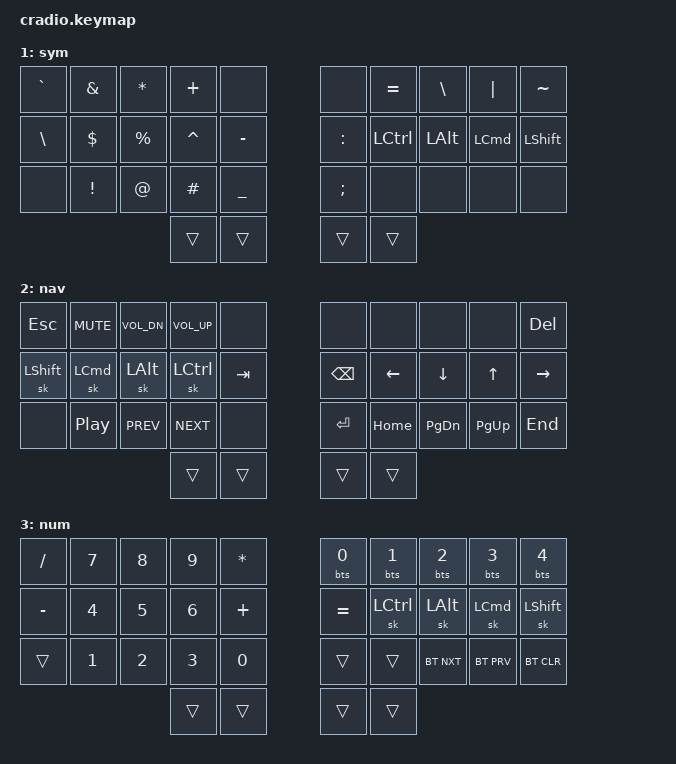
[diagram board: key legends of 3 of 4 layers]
// Copyright (c) 2022 The ZMK Contributors
// SPDX-License-Identifier: MIT

#include <behaviors.dtsi>
#include <dt-bindings/zmk/keys.h>
#include <dt-bindings/zmk/bt.h>
#include <dt-bindings/zmk/outputs.h>

// Cannot use it with keymap-drawer
/* #include "zmk-helpers/key-labels/34.h" */
#include "keypos.h"

#define BASE 0
#define SYM 1
#define NAV 2
#define NUM 3
#define VOL_DN C_VOL_DN
#define VOL_UP C_VOL_UP

#define HRML(k1,k2,k3) &hml LCMD k1  &hml LALT k2 &hml LCTRL k3
#define HRMR(k1,k2,k3) &hmr LCTRL k1 &hmr LALT k2 &hmr LCMD k3


&sk {
  release-after-ms = <2000>;
};

/ {
    macros {
        bts: bts {
            compatible = "zmk,behavior-macro-one-param";
            #binding-cells = <1>;
            bindings
                = <&out OUT_BLE>
                , <&macro_param_1to2>
                , <&bt BT_SEL MACRO_PLACEHOLDER>
                ;
        };
    };
};


/ {
    behaviors {
        hml: hml {
            compatible = "zmk,behavior-hold-tap";
            flavor = "balanced";
            tapping-term-ms = <220>;
            quick-tap-ms = <175>;                // repeat on tap-into-hold
            require-prior-idle-ms = <150>;
            #binding-cells = <2>;
            bindings = <&kp>, <&kp>;
            hold-trigger-key-positions = <KEYS_R THUMBS>;
            hold-trigger-on-release;             // delay positional check until key-release
        };

        hmr: hmr {
            compatible = "zmk,behavior-hold-tap";
            flavor = "balanced";
            tapping-term-ms = <220>;
            quick-tap-ms = <175>;                // repeat on tap-into-hold
            require-prior-idle-ms = <150>;
            #binding-cells = <2>;
            bindings = <&kp>, <&kp>;
            hold-trigger-key-positions = <KEYS_L THUMBS>;
            hold-trigger-on-release;             // delay positional check until key-release
        };

        lpar_lt: lpar_lt {
            compatible = "zmk,behavior-mod-morph";
            mods = <(MOD_LSFT | MOD_RSFT)>;
            #binding-cells = <0>;
            bindings = <&kp LPAR>, <&kp LT>;
        };

        rpar_gt: rpar_gt {
            compatible = "zmk,behavior-mod-morph";
            mods = <(MOD_LSFT | MOD_RSFT)>;
            #binding-cells = <0>;
            bindings = <&kp RPAR>, <&kp GT>;
        };

        lbrc_lbkt: lbrc_lbkt {
            compatible = "zmk,behavior-mod-morph";
            mods = <(MOD_LSFT | MOD_RSFT)>;
            #binding-cells = <0>;
            bindings = <&kp LBRC>, <&kp LBKT>;
        };

        rbrc_rbkt: rbrc_rbkt {
            compatible = "zmk,behavior-mod-morph";
            mods = <(MOD_LSFT | MOD_RSFT)>;
            #binding-cells = <0>;
            bindings = <&kp RBRC>, <&kp RBKT>;
        };
    };

    conditional_layers {
        compatible = "zmk,conditional-layers";
        tri_layer {
            if-layers = <SYM NAV>;
            then-layer = <NUM>;
        };
    };

    combos {
        compatible = "zmk,combos";

        combo_escape {
            timeout-ms = <25>;
            key-positions = <LT2 LT1>;
            bindings = <&kp ESCAPE>;
            layers = <BASE>;
        };
        combo_tab {
            timeout-ms = <25>;
            key-positions = <LM2 LM1>;
            bindings = <&kp TAB>;
            layers = <BASE>;
        };


        combo_backspace {
            timeout-ms = <25>;
            key-positions = <RT2 RT3>;
            bindings = <&kp BACKSPACE>;
            layers = <BASE>;
        };
        combo_enter {
            timeout-ms = <25>;
            key-positions = <RM1 RM2>;
            bindings = <&kp ENTER>;
            layers = <BASE>;
        };

        combo_lpar {
            timeout-ms = <50>;
            key-positions = <LT1 LM1>;
            bindings = <&lpar_lt>;
            layers = <BASE>;
        };
        combo_rpar {
            timeout-ms = <50>;
            key-positions = <RT1 RM1>;
            bindings = <&rpar_gt>;
            layers = <BASE>;
        };

        combo_lbrc {
            timeout-ms = <50>;
            key-positions = <LT2 LM2>;
            bindings = <&lbrc_lbkt>;
            layers = <BASE>;
        };
        combo_rbrc {
            timeout-ms = <50>;
            key-positions = <RT2 RM2>;
            bindings = <&rbrc_rbkt>;
            layers = <BASE>;
        };

        combo_boot {
            timeout-ms = <40>;
            key-positions = <LB4 LB3>;
            bindings = <&bootloader>;
            layers = <BASE>;
        };
    };

    keymap {
        compatible = "zmk,keymap";
        base {
            bindings = <
        //╭──────────┬──────────┬──────────┬──────────┬──────────╮   ╭──────────┬──────────┬──────────┬──────────┬──────────╮
        //│  Q       │  W       │  F       │  P       │  B       │   │  J       │  L       │  U       │  Y       │  '       │
            &kp Q      &kp W      &kp F      &kp P      &kp B          &kp J      &kp L      &kp U      &kp Y      &kp SQT
        //├──────────┼──────────┼──────────┼──────────┼──────────┤   ├──────────┼──────────┼──────────┼──────────┼──────────┤
        //│  A       │  R       │  S       │  T       │  G       │   │  M       │  N       │  E       │  I       │  O       │
            &kp A      HRML(R,     S,         T)        &kp G          &kp M      HRMR(N,     E,         I)      &kp O
        //├──────────┼──────────┼──────────┼──────────┼──────────┤   ├──────────┼──────────┼──────────┼──────────┼──────────┤
        //│  Z       │  X       │  C       │  D       │  V       │   │  K       │  H       │ , <      │ . >      │ / ?      │
            &kp Z      &kp X      &kp C      &kp D      &kp V          &kp K      &kp H      &kp COMMA  &kp DOT    &kp FSLH
        //╰──────────┴──────────┴──────────┼──────────┼──────────┤   ├──────────┼──────────┼──────────┴──────────┴──────────╯
                                            &mo NAV     &kp LSHFT      &kp SPC    &mo SYM
        //                                 ╰──────────┴──────────╯   ╰──────────┴──────────╯
            >;
        };

        sym {
            bindings = <
        //╭──────────┬──────────┬──────────┬──────────┬──────────╮   ╭──────────┬──────────┬──────────┬──────────┬──────────╮
        //│  `       │  &       │  *       │  +       │          │   │          │  =       │  \       │  |       │  ~       │
            &kp GRAVE  &kp AMPS   &kp STAR   &kp PLUS   &none          &none      &kp EQUAL  &kp BSLH   &kp PIPE   &kp TILDE
        //├──────────┼──────────┼──────────┼──────────┼──────────┤   ├──────────┼──────────┼──────────┼──────────┼──────────┤
        //│  \       │  $       │  %       │  ^       │  -       │   │  :       │          │          │          │          │
            &kp BSLH   &kp DLLR   &kp PRCNT  &kp CARET  &kp MINUS      &kp COLON  &kp LCTRL  &kp LALT   &kp LCMD   &kp LSHFT
        //├──────────┼──────────┼──────────┼──────────┼──────────┤   ├──────────┼──────────┼──────────┼──────────┼──────────┤
        //│          │  !       │  @       │  #       │  _       │   │  ;       │          │          │          │          │
            &none      &kp EXCL   &kp AT     &kp HASH   &kp UNDER      &kp SEMI   &none      &none      &none      &none
        //╰──────────┴──────────┴──────────┼──────────┼──────────┤   ├──────────┼──────────┼──────────┴──────────┴──────────╯
                                             &trans     &trans         &trans     &trans
        //                                 ╰──────────┴──────────╯   ╰──────────┴──────────╯
            >;
        };

        nav {
            bindings = <
        //╭──────────┬──────────┬──────────┬──────────┬──────────╮   ╭──────────┬──────────┬──────────┬──────────┬──────────╮
        //│  ESCAPE  │  MUTE    │ VOL DOWN │  VOL UP  │          │   │          │          │          │          │  DELETE  │
            &kp ESC   &kp C_MUTE &kp VOL_DN &kp VOL_UP  &none          &none     &none       &none       &none     &kp DEL
        //├──────────┼──────────┼──────────┼──────────┼──────────┤   ├──────────┼──────────┼──────────┼──────────┼──────────┤
        //│  SHIFT   │  CMD     │  ALT     │  CTRL    │  TAB     │   │ BSPC     │  LEFT    │  DOWN    │  UP      │ RIGHT    │
            &sk LSHFT  &sk LCMD   &sk LALT   &sk LCTRL  &kp TAB        &kp BSPC  &kp LEFT   &kp DOWN   &kp UP     &kp RIGHT
        //├──────────┼──────────┼──────────┼──────────┼──────────┤   ├──────────┼──────────┼──────────┼──────────┼──────────┤
        //│          │  PLAY    │ PREVIOUS │  NEXT    │          │   │  ENTER   │  HOME    │ PG_DOWN   │ PG UP    │ END
            &none      &kp C_PP  &kp C_PREV &kp C_NEXT  &none          &kp ENTER &kp HOME  &kp PG_DN  &kp PG_UP   &kp END
        //╰──────────┴──────────┴──────────┼──────────┼──────────┤   ├──────────┼──────────┼──────────┴──────────┴──────────╯
                                             &trans     &trans         &trans     &trans
        //                                 ╰──────────┴──────────╯   ╰──────────┴──────────╯
            >;
        };

        num {
            bindings = <
        //╭──────────┬──────────┬──────────┬──────────┬──────────╮   ╭──────────┬──────────┬──────────┬──────────┬──────────╮
        //│  /       │  7       │  8       │  9       │  *       │   │          │          │          │          │          │
            &kp SLASH  &kp N7     &kp N8     &kp N9     &kp STAR       &bts 0     &bts 1     &bts 2     &bts 3     &bts 4
        //├──────────┼──────────┼──────────┼──────────┼──────────┤   ├──────────┼──────────┼──────────┼──────────┼──────────┤
        //│  -       │  4       │  5       │  6       │  +       │   │  =       │  CTRL    │  ALT     │  CMD     │  SHIFT   │
            &kp MINUS  &kp N4     &kp N5     &kp N6     &kp PLUS       &kp EQUAL  &sk LCTRL  &sk LALT   &sk LCMD   &sk LSHFT
        //├──────────┼──────────┼──────────┼──────────┼──────────┤   ├──────────┼──────────┼──────────┼──────────┼──────────┤
        //│          │  1       │  2       │  3       │  0       │   │          │          │          │          │          │
            &trans     &kp N1     &kp N2     &kp N3     &kp N0         &trans     &trans     &bt BT_NXT &bt BT_PRV &bt BT_CLR
        //╰──────────┴──────────┴──────────┼──────────┼──────────┤   ├──────────┼──────────┼──────────┴──────────┴──────────╯
                                             &trans     &trans         &trans     &trans
        //                                 ╰──────────┴──────────╯   ╰──────────┴──────────╯
            >;
        };
    };
};
